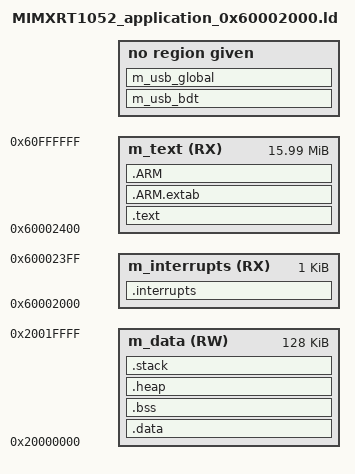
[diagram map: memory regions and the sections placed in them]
/*
** ###################################################################
**     Processors:          MIMXRT1052CVJ5B
**                          MIMXRT1052CVL5B
**                          MIMXRT1052DVJ6B
**                          MIMXRT1052DVL6B
**
**     Compiler:            GNU C Compiler
**     Reference manual:    IMXRT1050RM Rev.1, 03/2018
**     Version:             rev. 0.1, 2017-01-10
**     Build:               b180509
**
**     Abstract:
**         Linker file for the GNU C Compiler
**
**     Copyright (c) 2015 Freescale Semiconductor, Inc.
**     Copyright 2016-2018 NXP
**     All rights reserved.
**
**     SPDX-License-Identifier: BSD-3-Clause
**
**     http:                 www.nxp.com
**     mail:                 support@nxp.com
**
** ###################################################################
*/

/* Entry Point */
ENTRY(Reset_Handler)

HEAP_SIZE  = DEFINED(__heap_size__)  ? __heap_size__  : 0x0;
STACK_SIZE = DEFINED(__stack_size__) ? __stack_size__ : 0x0400;

/* Specify the memory areas */
/* Memory region from [0x6000_0000-0x6000_1FFF] is reserved for ROM code */
MEMORY
{
  m_interrupts          (RX)  : ORIGIN = 0x60002000, LENGTH = 0x00000400
  m_text                (RX)  : ORIGIN = 0x60002400, LENGTH = 0x00FFDC00
  m_data                (RW)  : ORIGIN = 0x20000000, LENGTH = 0x00020000
}

GROUP (
  libgcc.a
  libc_nano.a
  libm.a
  libcr_newlib_none.a
)

/* Define output sections */
SECTIONS
{
  /* The startup code goes first into internal RAM */
  .interrupts :
  {
    __VECTOR_TABLE = .;
    . = ALIGN(4);
    KEEP(*(.isr_vector))     /* Startup code */
    . = ALIGN(4);
  } > m_interrupts

  __VECTOR_RAM = __VECTOR_TABLE;
  __RAM_VECTOR_TABLE_SIZE_BYTES = 0x0;

  /* The program code and other data goes into internal RAM */
  .text :
  {
    . = ALIGN(4);
    *(.text)                 /* .text sections (code) */
    *(.text*)                /* .text* sections (code) */
    *(.rodata)               /* .rodata sections (constants, strings, etc.) */
    *(.rodata*)              /* .rodata* sections (constants, strings, etc.) */
    . = ALIGN(4);
  } > m_text

  .ARM.extab :
  {
    *(.ARM.extab* .gnu.linkonce.armextab.*)
  } > m_text

  .ARM :
  {
    __exidx_start = .;
    *(.ARM.exidx*)
    __exidx_end = .;
  } > m_text

  __etext = .;    /* define a global symbol at end of code */
  __DATA_ROM = .; /* Symbol is used by startup for data initialization */

  .data : AT(__DATA_ROM)
  {
    . = ALIGN(4);
    __DATA_RAM = .;
    __data_start__ = .;      /* create a global symbol at data start */
    *(.data)                 /* .data sections */
    *(.data*)                /* .data* sections */
    . = ALIGN(4);
    __data_end__ = .;        /* define a global symbol at data end */
  } > m_data

  __DATA_END = __DATA_ROM + (__data_end__ - __data_start__);
  text_end = ORIGIN(m_text) + LENGTH(m_text);
  ASSERT(__DATA_END <= text_end, "region m_text overflowed with text and data")

  USB_RAM_GAP = DEFINED(__usb_ram_size__) ? __usb_ram_size__ : 0x00;
  /* Uninitialized data section */
  .bss :
  {
    /* This is used by the startup in order to initialize the .bss section */
    . = ALIGN(4);
    __START_BSS = .;
    __bss_start__ = .;
    *(.bss)
    *(.bss*)
    . = ALIGN(512);
    USB_RAM_START = .;
    . += USB_RAM_GAP;
    *(COMMON)
    . = ALIGN(4);
    __bss_end__ = .;
    __END_BSS = .;
  } > m_data

  .heap :
  {
    . = ALIGN(8);
    __end__ = .;
    PROVIDE(end = .);
    __HeapBase = .;
    . += HEAP_SIZE;
    __HeapLimit = .;
    __heap_limit = .; /* Add for _sbrk */
  } > m_data

  .stack :
  {
    . = ALIGN(8);
    . += STACK_SIZE;
  } > m_data

  m_usb_bdt USB_RAM_START (NOLOAD) :
  {
    *(m_usb_bdt)
    USB_RAM_BDT_END = .;
  }

  m_usb_global USB_RAM_BDT_END (NOLOAD) :
  {
    *(m_usb_global)
  }

  /* Initializes stack on the end of block */
  __StackTop   = ORIGIN(m_data) + LENGTH(m_data);
  __StackLimit = __StackTop - STACK_SIZE;
  PROVIDE(__stack = __StackTop);

  .ARM.attributes 0 : { *(.ARM.attributes) }

  ASSERT(__StackLimit >= __HeapLimit, "region m_data overflowed with stack and heap")
}

